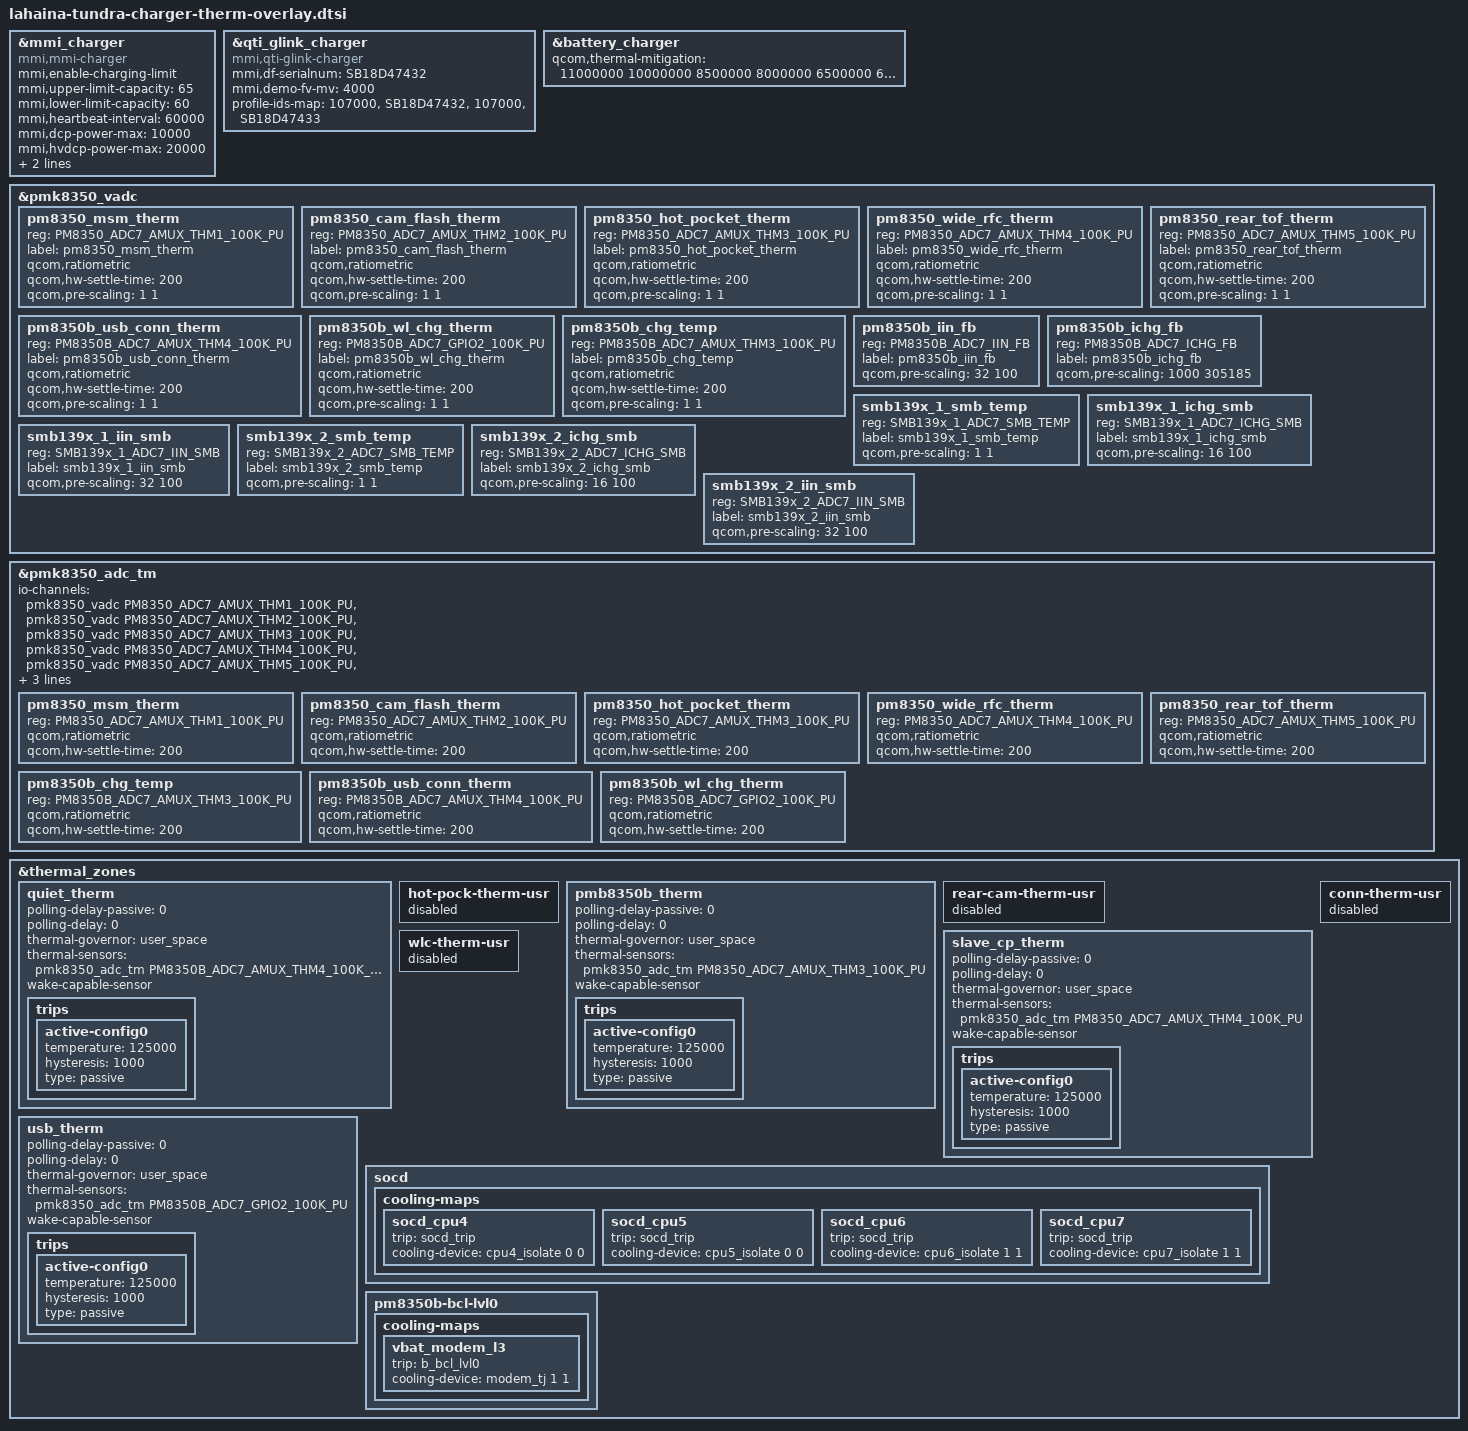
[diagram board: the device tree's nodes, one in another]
#include "moto_therm_sys_temp.dtsi"

&mmi_charger {
        compatible = "mmi,mmi-charger";
        mmi,enable-charging-limit;
        mmi,upper-limit-capacity = <65>;
        mmi,lower-limit-capacity = <60>;
        mmi,heartbeat-interval = <60000>;
        mmi,dcp-power-max = <10000>;
        mmi,hvdcp-power-max = <20000>;
        mmi,pd-power-max = <30000>;
	mmi,factory-kill-debounce-ms = <3000>;
};

&qti_glink_charger {
        compatible = "mmi,qti-glink-charger";
        mmi,df-serialnum = "SB18D47432";
        mmi,demo-fv-mv = <4000>;
        profile-ids-map = "107000", "SB18D47432","107000","SB18D47433";
};

&battery_charger {
        qcom,thermal-mitigation = <11000000 10000000 8500000  8000000 6500000 6000000 5000000 4000000 3000000 2500000 1000000 500000>;
};

&pmk8350_vadc {

	/delete-node/ pm8350_msm_therm;
	/delete-node/ pm8350_cam_flash_therm;
	/delete-node/ pm8350_hot_pocket_therm;
	/delete-node/ pm8350_wide_rfc_therm;
	/delete-node/ pm8350_rear_tof_therm;
	/delete-node/ pm8350b_usb_conn_therm;
	/delete-node/ pm8350b_wl_chg_therm;
	/delete-node/ pm8350b_chg_temp;
	/delete-node/ pm8350b_iin_fb;
	/delete-node/ pm8350b_ichg_fb;
	/delete-node/ smb139x_1_smb_temp;
	/delete-node/ smb139x_1_ichg_smb;
	/delete-node/ smb139x_1_iin_smb;
	/delete-node/ smb139x_2_smb_temp;
	/delete-node/ smb139x_2_ichg_smb;
	/delete-node/ smb139x_2_iin_smb;

	pm8350_msm_therm {
		reg = <PM8350_ADC7_AMUX_THM1_100K_PU>;
		label = "pm8350_msm_therm";
		qcom,ratiometric;
		qcom,hw-settle-time = <200>;
		qcom,pre-scaling = <1 1>;
	};

	pm8350_cam_flash_therm {
		reg = <PM8350_ADC7_AMUX_THM2_100K_PU>;
		label = "pm8350_cam_flash_therm";
		qcom,ratiometric;
		qcom,hw-settle-time = <200>;
		qcom,pre-scaling = <1 1>;
	};

	pm8350_hot_pocket_therm {
		reg = <PM8350_ADC7_AMUX_THM3_100K_PU>;
		label = "pm8350_hot_pocket_therm";
		qcom,ratiometric;
		qcom,hw-settle-time = <200>;
		qcom,pre-scaling = <1 1>;
	};

	pm8350_wide_rfc_therm {
		reg = <PM8350_ADC7_AMUX_THM4_100K_PU>;
		label = "pm8350_wide_rfc_therm";
		qcom,ratiometric;
		qcom,hw-settle-time = <200>;
		qcom,pre-scaling = <1 1>;
	};

	pm8350_rear_tof_therm {
		reg = <PM8350_ADC7_AMUX_THM5_100K_PU>;
		label = "pm8350_rear_tof_therm";
		qcom,ratiometric;
		qcom,hw-settle-time = <200>;
		qcom,pre-scaling = <1 1>;
	};

	pm8350b_usb_conn_therm {
		reg = <PM8350B_ADC7_AMUX_THM4_100K_PU>;
		label = "pm8350b_usb_conn_therm";
		qcom,ratiometric;
		qcom,hw-settle-time = <200>;
		qcom,pre-scaling = <1 1>;
	};

        pm8350b_wl_chg_therm {
                reg = <PM8350B_ADC7_GPIO2_100K_PU>;
                label = "pm8350b_wl_chg_therm";
                qcom,ratiometric;
                qcom,hw-settle-time = <200>;
                qcom,pre-scaling = <1 1>;
        };

	pm8350b_chg_temp {
		reg = <PM8350B_ADC7_AMUX_THM3_100K_PU>;
		label = "pm8350b_chg_temp";
                qcom,ratiometric;
                qcom,hw-settle-time = <200>;
                qcom,pre-scaling = <1 1>;
	};

	pm8350b_iin_fb {
		reg = <PM8350B_ADC7_IIN_FB>;
		label = "pm8350b_iin_fb";
		qcom,pre-scaling = <32 100>;
	};

	pm8350b_ichg_fb {
		reg = <PM8350B_ADC7_ICHG_FB>;
		label = "pm8350b_ichg_fb";
		qcom,pre-scaling = <1000 305185>;
	};

	smb139x_1_smb_temp {
		reg = <SMB139x_1_ADC7_SMB_TEMP>;
		label = "smb139x_1_smb_temp";
		qcom,pre-scaling = <1 1>;
	};

	smb139x_1_ichg_smb {
		reg = <SMB139x_1_ADC7_ICHG_SMB>;
		label = "smb139x_1_ichg_smb";
		qcom,pre-scaling = <16 100>;
	};

	smb139x_1_iin_smb {
		reg = <SMB139x_1_ADC7_IIN_SMB>;
		label = "smb139x_1_iin_smb";
		qcom,pre-scaling = <32 100>;
	};

	smb139x_2_smb_temp {
		reg = <SMB139x_2_ADC7_SMB_TEMP>;
		label = "smb139x_2_smb_temp";
		qcom,pre-scaling = <1 1>;
	};

	smb139x_2_ichg_smb {
		reg = <SMB139x_2_ADC7_ICHG_SMB>;
		label = "smb139x_2_ichg_smb";
		qcom,pre-scaling = <16 100>;
	};

	smb139x_2_iin_smb {
		reg = <SMB139x_2_ADC7_IIN_SMB>;
		label = "smb139x_2_iin_smb";
		qcom,pre-scaling = <32 100>;
	};
};

&pmk8350_adc_tm {
	/delete-property/ io-channels;
	io-channels = <&pmk8350_vadc PM8350_ADC7_AMUX_THM1_100K_PU>,
			<&pmk8350_vadc PM8350_ADC7_AMUX_THM2_100K_PU>,
			<&pmk8350_vadc PM8350_ADC7_AMUX_THM3_100K_PU>,
			<&pmk8350_vadc PM8350_ADC7_AMUX_THM4_100K_PU>,
			<&pmk8350_vadc PM8350_ADC7_AMUX_THM5_100K_PU>,
			<&pmk8350_vadc PM8350B_ADC7_AMUX_THM3_100K_PU>,
			<&pmk8350_vadc PM8350B_ADC7_AMUX_THM4_100K_PU>,
			<&pmk8350_vadc PM8350B_ADC7_GPIO2_100K_PU>;/*
			<&pmk8350_vadc PMK8350_ADC7_AMUX_THM1_100K_PU>;*/

	/delete-node/ pm8350_msm_therm;
	/delete-node/ pm8350_cam_flash_therm;
	/delete-node/ pm8350_hot_pocket_therm;
	/delete-node/ pm8350_wide_rfc_therm;
	/delete-node/ pm8350_rear_tof_therm;
	/delete-node/ pm8350b_chg_conn_therm;
	/delete-node/ pm8350b_usb_conn_therm;
	/delete-node/ pm8350b_wl_chg_therm;
	/delete-node/ pmk8350_xo_therm;

	pm8350_msm_therm {
		reg = <PM8350_ADC7_AMUX_THM1_100K_PU>;
		qcom,ratiometric;
		qcom,hw-settle-time = <200>;
	};

	pm8350_cam_flash_therm {
		reg = <PM8350_ADC7_AMUX_THM2_100K_PU>;
		qcom,ratiometric;
		qcom,hw-settle-time = <200>;
	};

	pm8350_hot_pocket_therm {
		reg = <PM8350_ADC7_AMUX_THM3_100K_PU>;
		qcom,ratiometric;
		qcom,hw-settle-time = <200>;
	};

	pm8350_wide_rfc_therm {
		reg = <PM8350_ADC7_AMUX_THM4_100K_PU>;
		qcom,ratiometric;
		qcom,hw-settle-time = <200>;
	};

	pm8350_rear_tof_therm {
		reg = <PM8350_ADC7_AMUX_THM5_100K_PU>;
		qcom,ratiometric;
		qcom,hw-settle-time = <200>;
	};

	pm8350b_chg_temp {
		reg = <PM8350B_ADC7_AMUX_THM3_100K_PU>;
		qcom,ratiometric;
		qcom,hw-settle-time = <200>;
	};

	pm8350b_usb_conn_therm {
		reg = <PM8350B_ADC7_AMUX_THM4_100K_PU>;
		qcom,ratiometric;
		qcom,hw-settle-time = <200>;
	};

        pm8350b_wl_chg_therm {
                reg = <PM8350B_ADC7_GPIO2_100K_PU>;
                qcom,ratiometric;
                qcom,hw-settle-time = <200>;
        };
/*
	pmk8350_xo_therm {
		reg = <PMK8350_ADC7_AMUX_THM1_100K_PU>;
		qcom,ratiometric;
		qcom,hw-settle-time = <200>;
	};*/
};

&thermal_zones {

/*	skin-msm-therm-usr {
		status = "disabled";
	};

	skin-msm-therm-usr {
		polling-delay-passive = <0>;
		polling-delay = <0>;
		thermal-governor = "user_space";
		thermal-sensors = <&pmk8350_adc_tm PM8350_ADC7_AMUX_THM1_100K_PU>;
		wake-capable-sensor;
		trips {
			active-config0 {
				temperature = <125000>;
				hysteresis = <1000>;
				type = "passive";
			};

			active-config1 {
				temperature = <125000>;
				hysteresis = <1000>;
				type = "passive";
			};
		};
	};

	camera-therm-usr {
		status = "disabled";
	};
	camera-therm-usr {
		polling-delay-passive = <0>;
		polling-delay = <0>;
		thermal-governor = "user_space";
		thermal-sensors = <&pmk8350_adc_tm PM8350_ADC7_AMUX_THM2_100K_PU>;
		wake-capable-sensor;
		trips {
			active-config0 {
				temperature = <125000>;
				hysteresis = <1000>;
				type = "passive";
			};
		};
	};
*/
	quiet_therm {
		polling-delay-passive = <0>;
		polling-delay = <0>;
		thermal-governor = "user_space";
		thermal-sensors = <&pmk8350_adc_tm PM8350B_ADC7_AMUX_THM4_100K_PU>;
		wake-capable-sensor;
		trips {
			active-config0 {
				temperature = <125000>;
				hysteresis = <1000>;
				type = "passive";
			};
		};
	};

	hot-pock-therm-usr {
		status = "disabled";
	};
	pmb8350b_therm {
		polling-delay-passive = <0>;
		polling-delay = <0>;
		thermal-governor = "user_space";
		thermal-sensors = <&pmk8350_adc_tm PM8350_ADC7_AMUX_THM3_100K_PU>;
		wake-capable-sensor;
		trips {
			active-config0 {
				temperature = <125000>;
				hysteresis = <1000>;
				type = "passive";
			};
		};
	};

	rear-cam-therm-usr {
		status = "disabled";
	};
	slave_cp_therm {
		polling-delay-passive = <0>;
		polling-delay = <0>;
		thermal-governor = "user_space";
		thermal-sensors = <&pmk8350_adc_tm PM8350_ADC7_AMUX_THM4_100K_PU>;
		wake-capable-sensor;
		trips {
			active-config0 {
				temperature = <125000>;
				hysteresis = <1000>;
				type = "passive";
			};
		};
	};

	conn-therm-usr {
		status = "disabled";
	};
	wlc-therm-usr {
                status = "disabled";
        };
	usb_therm {
		polling-delay-passive = <0>;
		polling-delay = <0>;
		thermal-governor = "user_space";
		thermal-sensors = <&pmk8350_adc_tm PM8350B_ADC7_GPIO2_100K_PU>;
		wake-capable-sensor;
		trips {
			active-config0 {
				temperature = <125000>;
				hysteresis = <1000>;
				type = "passive";
			};
		};
	};
	
	socd {
                cooling-maps {
		       socd_cpu4 {
                                trip = <&socd_trip>;
                                cooling-device = <&cpu4_isolate 0 0>;
                       };
                       socd_cpu5 {
                                trip = <&socd_trip>;
                                cooling-device = <&cpu5_isolate 0 0>;
                       };
                       socd_cpu6 {
                                trip = <&socd_trip>;
                                cooling-device = <&cpu6_isolate 1 1>;
                       };
                       socd_cpu7 {
                                trip = <&socd_trip>;
                                cooling-device = <&cpu7_isolate 1 1>;
                       };
                };
        };

	pm8350b-bcl-lvl0 {
                cooling-maps {
                        vbat_modem_l3 {
                                trip = <&b_bcl_lvl0>;
                                cooling-device = <&modem_tj 1 1>;
                        };
		};
	};
/*
	pa_therm1 {
		polling-delay-passive = <0>;
		polling-delay = <0>;
		thermal-governor = "user_space";
		thermal-sensors = <&pmk8350_adc_tm PM8350_ADC7_GPIO1_100K_PU>;
		wake-capable-sensor;
		trips {
			active-config0 {
				temperature = <125000>;
				hysteresis = <1000>;
				type = "passive";
			};
		};
	};
	pa_therm2 {
		polling-delay-passive = <0>;
		polling-delay = <0>;
		thermal-governor = "user_space";
		thermal-sensors = <&pmk8350_adc_tm PM8350_ADC7_GPIO4_100K_PU>;
		wake-capable-sensor;
		trips {
			active-config0 {
				temperature = <125000>;
				hysteresis = <1000>;
				type = "passive";
			};
		};
	};
*/
/*
	pm8350c-bcl-lvl0 {
		status = "disabled";
	};
	pm8350c-bcl-lvl1 {
		status = "disabled";
	};
	pm8350c-bcl-lvl2 {
		status = "disabled";
	};

	modem-mmw-pa1-usr {
		status = "disabled";
	};
	mmwpn_therm {
		polling-delay-passive = <0>;
		polling-delay = <0>;
		thermal-governor = "user_space";
		thermal-sensors = <&qmi_sensor
				(QMI_MODEM_INST_ID+QMI_MMW_PA1)>;
		trips {
			active-config0 {
				temperature = <125000>;
				hysteresis = <1000>;
				type = "passive";
			};
		};
	};

	modem-mmw-pa2-usr {
		status = "disabled";
	};
	mmwpe_therm {
		polling-delay-passive = <0>;
		polling-delay = <0>;
		thermal-governor = "user_space";
		thermal-sensors = <&qmi_sensor
				(QMI_MODEM_INST_ID+QMI_MMW_PA2)>;
		trips {
			active-config0 {
				temperature = <125000>;
				hysteresis = <1000>;
				type = "passive";
			};
		};
	};
	modem-sub6-pa1-step {
		status = "disabled";
	};
	modem-lte-pa2-step {
		status = "disabled";
	};
*/
};

//&battery_charger {
//	no-conn-therm;
//};
